# STM32H743 register map
File version: 2.4
CPU: CM7 r0p1, little endian, MPU, FPU, 4 interrupt priority bits
Registers are 32-bit, read-write, reset 0x0 unless marked. A register's access mark holds for its fields unless they carry their own. Offsets are from the block's base; [hi:lo] are bit positions; {n}, {i} and the like mark numbered series.

## TIM1 — 高级控制定时器
Base 0x40010000
Same registers: TIM8 0x40010400
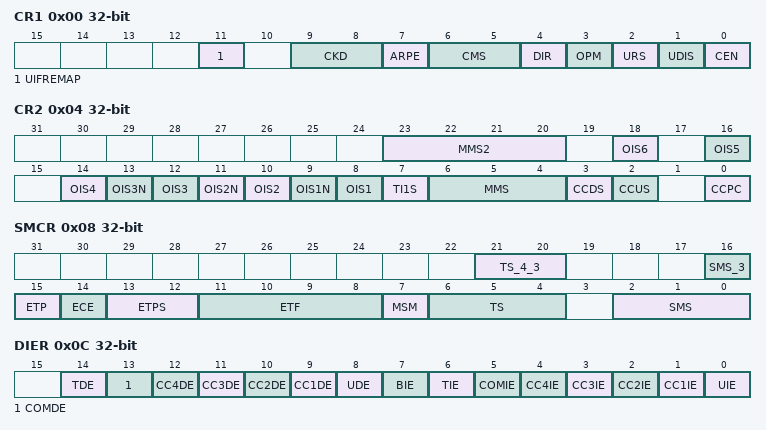
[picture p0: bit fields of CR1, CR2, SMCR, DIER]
0x00 CR1 — 控制寄存器 1
  [11] UIFREMAP — UIF 状态位重映射
  [9:8] CKD — 时钟分频
  [7] ARPE — 自动重载预装载使能
  [6:5] CMS — 中央对齐模式选择
  [4] DIR — 计数方向
  [3] OPM — 单脉冲模式
  [2] URS — 更新请求源
  [1] UDIS — 更新禁止
  [0] CEN — 计数器使能
0x04 CR2 — 控制寄存器 2
  [23:20] MMS2 — 主模式选择 2
  [2n+6] OIS{n} (n=1..6) — 输出空闲状态 {n}
  [13] OIS3N — 互补输出空闲状态 3
  [11] OIS2N — 互补输出空闲状态 2
  [9] OIS1N — 互补输出空闲状态 1
  [7] TI1S — TI1 选择
  [6:4] MMS — 主模式选择
  [3] CCDS — 捕获/比较 DMA 选择
  [2] CCUS — 捕获/比较控制更新选择
  [0] CCPC — 捕获/比较预装载控制
0x08 SMCR — 从模式控制寄存器
  [21:20] TS_4_3 — 触发源选择 - 位 4:3
  [16] SMS_3 — 从模式选择 - 位 3
  [15] ETP — 外部触发极性
  [14] ECE — 外部时钟使能
  [13:12] ETPS — 外部触发预分频器
  [11:8] ETF — 外部触发滤波器
  [7] MSM — 主/从模式
  [6:4] TS — 触发源选择
  [2:0] SMS — 从模式选择
0x0C DIER — DMA/中断使能寄存器
  [14] TDE — 触发 DMA 请求使能
  [13] COMDE — COM DMA 请求使能
  [n+8] CC{n}DE (n=1..4) — 捕获/比较 {n} DMA 请求使能
  [8] UDE — 更新 DMA 请求使能
  [7] BIE — 刹车中断使能
  [6] TIE — 触发中断使能
  [5] COMIE — COM 中断使能
  [n] CC{n}IE (n=1..4) — 捕获/比较 {n} 中断使能
  [0] UIE — 更新中断使能
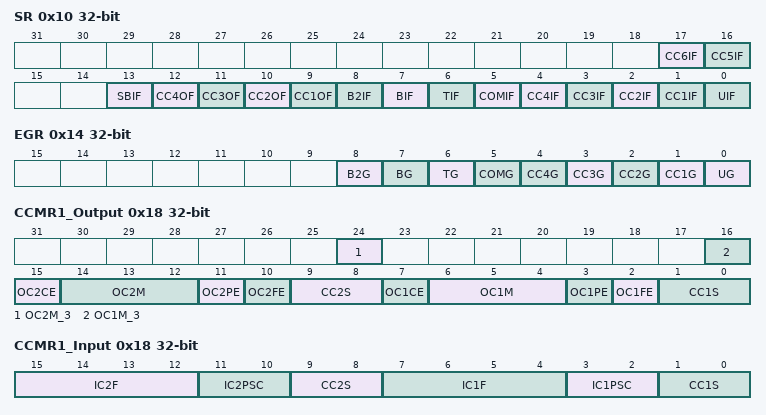
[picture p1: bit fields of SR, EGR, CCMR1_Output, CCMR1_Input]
0x10 SR — 状态寄存器
  [17] CC6IF — 比较 6 中断标志
  [16] CC5IF — 比较 5 中断标志
  [13] SBIF — 系统刹车中断标志
  [n+8] CC{n}OF (n=1..4) — 捕获/比较 {n} 重复捕获标志
  [8] B2IF — 刹车 2 中断标志
  [7] BIF — 刹车中断标志
  [6] TIF — 触发中断标志
  [5] COMIF — COM 中断标志
  [n] CC{n}IF (n=1..4) — 捕获/比较 {n} 中断标志
  [0] UIF — 更新中断标志
0x14 EGR wo — 事件生成寄存器
  [8] B2G — 刹车 2 事件生成
  [7] BG — 刹车事件生成
  [6] TG — 触发事件生成
  [5] COMG — 捕获/比较控制更新事件生成
  [n] CC{n}G (n=1..4) — 捕获/比较 {n} 事件生成
  [0] UG — 更新事件生成
0x18 CCMR1_Output — 捕获/比较模式寄存器 1（输出模式）
  [24] OC2M_3 — 输出比较 2 模式 - 位 3
  [16] OC1M_3 — 输出比较 1 模式 - 位 3
  [15] OC2CE — 输出比较 2 清零使能
  [14:12] OC2M — 输出比较 2 模式
  [11] OC2PE — 输出比较 2 预装载使能
  [10] OC2FE — 输出比较 2 快速使能
  [9:8] CC2S — 捕获/比较 2 选择
  [7] OC1CE — 输出比较 1 清零使能
  [6:4] OC1M — 输出比较 1 模式
  [3] OC1PE — 输出比较 1 预装载使能
  [2] OC1FE — 输出比较 1 快速使能
  [1:0] CC1S — 捕获/比较 1 选择
0x18 CCMR1_Input (alternate view of CCMR1_Output) — 捕获/比较模式寄存器 1（输入模式）
  [15:12] IC2F — 输入捕获 2 滤波器
  [11:10] IC2PSC — 输入捕获 2 预分频器
  [9:8] CC2S — 捕获/比较 2 选择
  [7:4] IC1F — 输入捕获 1 滤波器
  [3:2] IC1PSC — 输入捕获 1 预分频器
  [1:0] CC1S — 捕获/比较 1 选择
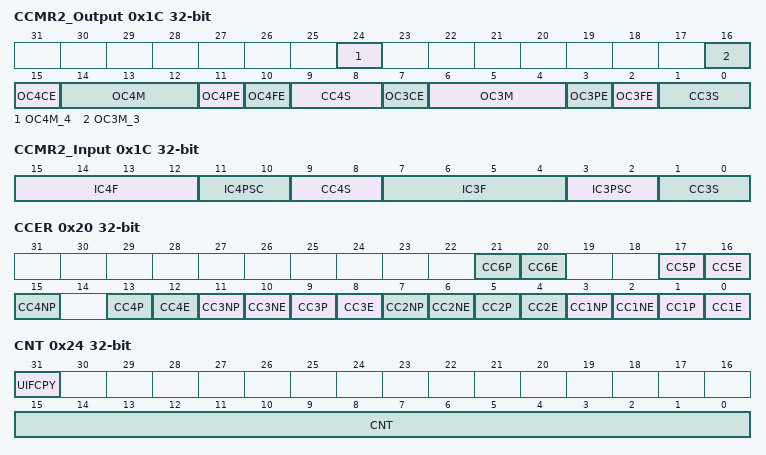
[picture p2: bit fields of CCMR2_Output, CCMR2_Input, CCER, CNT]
0x1C CCMR2_Output — 捕获/比较模式寄存器 2（输出模式）
  [24] OC4M_4 — 输出比较 4 模式 - 位 3
  [16] OC3M_3 — 输出比较 3 模式 - 位 3
  [15] OC4CE — 输出比较 4 清零使能
  [14:12] OC4M — 输出比较 4 模式
  [11] OC4PE — 输出比较 4 预装载使能
  [10] OC4FE — 输出比较 4 快速使能
  [9:8] CC4S — 捕获/比较 4 选择
  [7] OC3CE — 输出比较 3 清零使能
  [6:4] OC3M — 输出比较 3 模式
  [3] OC3PE — 输出比较 3 预装载使能
  [2] OC3FE — 输出比较 3 快速使能
  [1:0] CC3S — 捕获/比较 3 选择
0x1C CCMR2_Input (alternate view of CCMR2_Output) — 捕获/比较模式寄存器 2（输入模式）
  [15:12] IC4F — 输入捕获 4 滤波器
  [11:10] IC4PSC — 输入捕获 4 预分频器
  [9:8] CC4S — 捕获/比较 4 选择
  [7:4] IC3F — 输入捕获 3 滤波器
  [3:2] IC3PSC — 输入捕获 3 预分频器
  [1:0] CC3S — 捕获/比较 3 选择
0x20 CCER — 捕获/比较使能寄存器
  [4n-3] CC{n}P (n=1..6) — 捕获/比较 {n} 输出极性
  [4n-4] CC{n}E (n=1..6) — 捕获/比较 {n} 输出使能
  [4n-1] CC{n}NP (n=1..4) — 捕获/比较 {n} 互补输出极性
  [10] CC3NE — 捕获/比较 3 互补输出使能
  [6] CC2NE — 捕获/比较 2 互补输出使能
  [2] CC1NE — 捕获/比较 1 互补输出使能
0x24 CNT access per field — 计数器
  [31] UIFCPY ro — UIF 副本
  [15:0] CNT rw — 计数器值
0x28 PSC — 预分频器
  [15:0] PSC — 预分频器值
0x2C ARR — 自动重载寄存器
  [15:0] ARR — 自动重载值
0x30 RCR — 重复计数器寄存器
  [7:0] REP — 重复计数器值
0x34 CCR1 — 捕获/比较寄存器 1
  [15:0] CCR1 — 捕获/比较 1 值
0x38 CCR2 — 捕获/比较寄存器 2
  [15:0] CCR2 — 捕获/比较 2 值
0x3C CCR3 — 捕获/比较寄存器 3
  [15:0] CCR3 — 捕获/比较值
0x40 CCR4 — 捕获/比较寄存器 4
  [15:0] CCR4 — 捕获/比较值
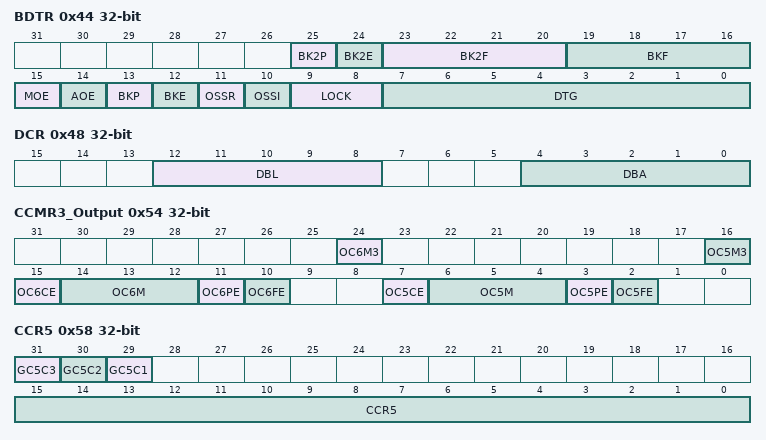
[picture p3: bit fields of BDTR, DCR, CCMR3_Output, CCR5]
0x44 BDTR — 刹车与死区寄存器
  [25] BK2P — 刹车 2 极性
  [24] BK2E — 刹车 2 使能
  [23:20] BK2F — 刹车 2 滤波器
  [19:16] BKF — 刹车滤波器
  [15] MOE — 主输出使能
  [14] AOE — 自动输出使能
  [13] BKP — 刹车极性
  [12] BKE — 刹车使能
  [11] OSSR — 运行模式关断状态选择
  [10] OSSI — 空闲模式关断状态选择
  [9:8] LOCK — 锁定配置
  [7:0] DTG — 死区发生器设置
0x48 DCR — DMA 控制寄存器
  [12:8] DBL — DMA 突发长度
  [4:0] DBA — DMA 基地址
0x4C DMAR — DMA 全传输地址寄存器
  [15:0] DMAB — DMA 突发访问寄存器
0x54 CCMR3_Output — 捕获/比较模式寄存器 3（输出模式）
  [24] OC6M3 — 输出比较 6 模式
  [16] OC5M3 — 输出比较 5 模式
  [15] OC6CE — 输出比较 6 清零使能
  [14:12] OC6M — 输出比较 6 模式
  [11] OC6PE — 输出比较 6 预装载使能
  [10] OC6FE — 输出比较 6 快速使能
  [7] OC5CE — 输出比较 5 清零使能
  [6:4] OC5M — 输出比较 5 模式
  [3] OC5PE — 输出比较 5 预装载使能
  [2] OC5FE — 输出比较 5 快速使能
0x58 CCR5 — 捕获/比较寄存器 5
  [31] GC5C3 — 通道 5 与通道 3 组合
  [30] GC5C2 — 通道 5 与通道 2 组合
  [29] GC5C1 — 通道 5 与通道 1 组合
  [15:0] CCR5 — 捕获/比较 5 值
0x5C CCR6 — 捕获/比较寄存器 6
  [15:0] CCR6 — 捕获/比较 6 值
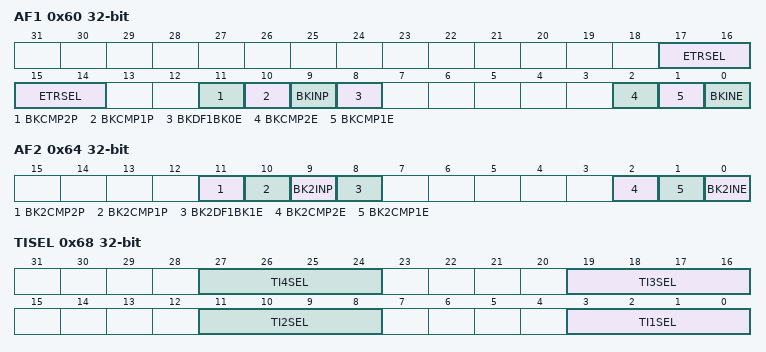
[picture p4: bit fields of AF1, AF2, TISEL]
0x60 AF1 — TIM1 复用功能选项寄存器 1
  [17:14] ETRSEL — ETR 源选择
  [11] BKCMP2P — BRK COMP2 输入极性
  [10] BKCMP1P — BRK COMP1 输入极性
  [9] BKINP — BRK BKIN 输入极性
  [8] BKDF1BK0E — BRK DFSDM1 刹车[0] 使能
  [2] BKCMP2E — BRK COMP2 使能
  [1] BKCMP1E — BRK COMP1 使能
  [0] BKINE — BRK BKIN 输入使能
0x64 AF2 — TIM1 复用功能寄存器 2
  [11] BK2CMP2P — BRK2 COMP2 输入极性
  [10] BK2CMP1P — BRK2 COMP1 输入极性
  [9] BK2INP — BRK2 BKIN2 输入极性
  [8] BK2DF1BK1E — BRK2 DFSDM1 刹车[1] 使能
  [2] BK2CMP2E — BRK2 COMP2 使能
  [1] BK2CMP1E — BRK2 COMP1 使能
  [0] BK2INE — BRK2 BKIN 输入使能
0x68 TISEL — TIM1 定时器输入选择寄存器
  [8n-5:8n-8] TI{n}SEL (n=1..4) — TI{n}[0] 至 TI{n}[15] 输入选择
